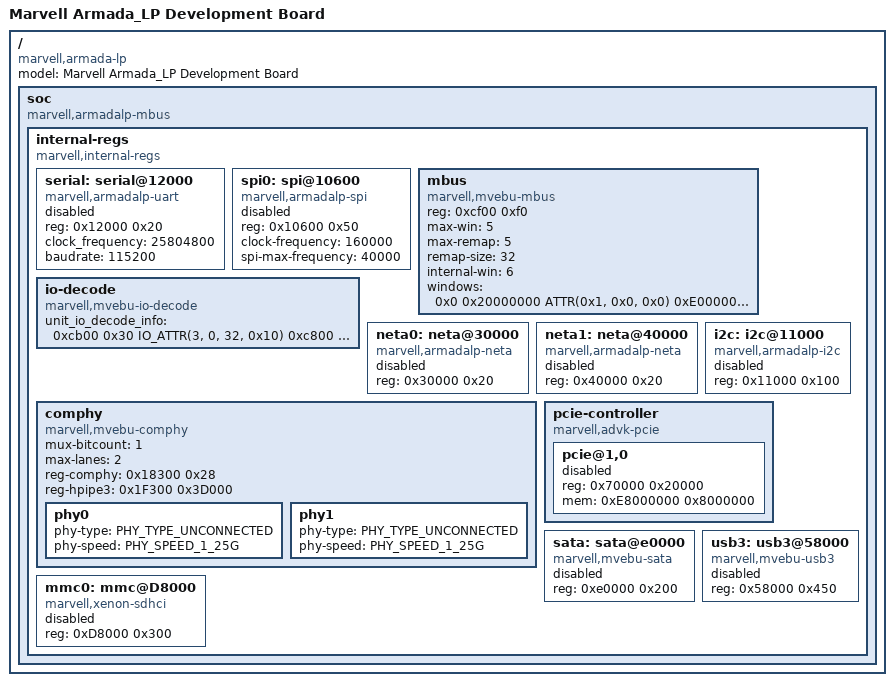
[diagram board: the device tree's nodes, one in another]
#define ATTR(remapped, target, attributes) (((remapped) << 12) | ((target) << 8) | (attributes))
#define IO_ATTR(max_win, max_remap, remap_size, win_offset) (((max_win) << 24) | ((max_remap) << 16) | ((remap_size) << 8) | (win_offset))

#include <dt-bindings/comphy/comphy_data.h>
/ {
	model = "Marvell Armada_LP Development Board";
	compatible = "marvell,armada-lp";

	#address-cells = <2>;
	#size-cells = <2>;

	soc {
	compatible = "marvell,armadalp-mbus";
	#address-cells = <1>;
	#size-cells = <0>;

		internal-regs {
			compatible = "marvell,internal-regs";
			#address-cells = <1>;
			#size-cells = <1>;
			ranges = <0x0000 0xd0000000 0x2000000>;

			serial: serial@12000 {
				compatible = "marvell,armadalp-uart";
				reg = <0x12000 0x20>;
				clock_frequency = <25804800>;
				baudrate = <115200>;
				status = "disabled";
			};

			spi0: spi@10600 {
				compatible = "marvell,armadalp-spi";
				reg = <0x10600 0x50>;
				#clock-cells = <0>;
				clock-frequency = <160000>;
				spi-max-frequency = <40000>;
				status = "disabled";
			};

			mbus {
				compatible = "marvell,mvebu-mbus";
				reg = <0xcf00 0xf0>;
				max-win = <5>;
				max-remap = <5>;
				remap-size = <32>;
				internal-win = <6>;
				windows = <0x0 0x20000000 ATTR(0x1, 0x0, 0x0)
					0xE0000000 0x8000000 ATTR(0x1, 0x5, 0x0)
					0xE8000000 0x8000000 ATTR(0x1, 0x2, 0x0)
					0xF0000000 0x20000 ATTR(0x1, 0x7, 0x0)
					0x80000000 0x10000000 ATTR(0x1, 0x3, 0x0)>;
			};

			io-decode {
				compatible = "marvell,mvebu-io-decode";
				#address-cells = <1>;
				#size-cells = <1>;

				unit_io_decode_info =
					/* reg_base, range, IO_ATTR(max_win, max_remap, remap_size, win_offset) */
					<0xcb00 0x30 IO_ATTR(3, 0, 32, 0x10) /* eMMC */
					0xc800 0x30 IO_ATTR(3, 0, 32, 0x10)> /* SATA */;
			};

			neta0: neta@30000 {
				compatible = "marvell,armadalp-neta";
				reg = <0x30000 0x20>;
				status = "disabled";
			};
			neta1: neta@40000 {
				compatible = "marvell,armadalp-neta";
				reg = <0x40000 0x20>;
				status = "disabled";
			};
			i2c: i2c@11000 {
				compatible = "marvell,armadalp-i2c";
				reg = <0x11000 0x100>;
				status = "disabled";
			};
			comphy {
				compatible = "marvell,mvebu-comphy", "marvell,comphy-armadalp";
				mux-bitcount = <1>;
				max-lanes = <2>;
				reg-comphy = <0x18300 0x28>;
				reg-hpipe3 = <0x1F300 0x3D000>;
				/* phy-type & phy-speed selection should be done in board level device tree */
				phy0 {
					phy-type = <PHY_TYPE_UNCONNECTED>;
					phy-speed = <PHY_SPEED_1_25G>;
				};
				phy1 {
					phy-type = <PHY_TYPE_UNCONNECTED>;
					phy-speed = <PHY_SPEED_1_25G>;
				};
			};
			pcie-controller {
				#address-cells = <1>;
				#size-cells = <1>;
				compatible = "marvell,advk-pcie";

				pcie@1,0 {
					reg = <0x70000 0x20000>;
					mem = <0xE8000000 0x8000000>;
					status = "disabled";
				};
			};
			sata: sata@e0000 {
				compatible = "marvell,mvebu-sata";
				reg = <0xe0000 0x200>;
				status = "disabled";
			};
			mmc0: mmc@D8000 {
				compatible = "marvell,xenon-sdhci";
				reg = <0xD8000 0x300>;
				status = "disabled";
			};
			usb3: usb3@58000 {
				compatible = "marvell,mvebu-usb3";
				reg = <0x58000 0x450>;
				status = "disabled";
			};
		};
	};
};
